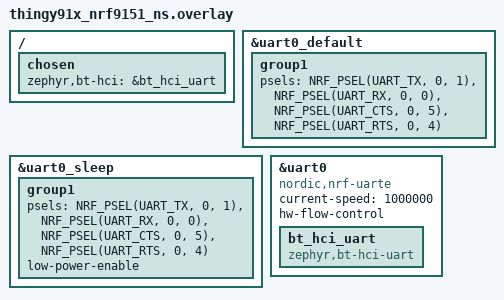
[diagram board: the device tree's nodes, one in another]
/*
 * Copyright (c) 2025 Golioth, Inc.
 *
 * SPDX-License-Identifier: Apache-2.0
 */

/ {
	chosen {
		zephyr,bt-hci = &bt_hci_uart;
		/delete-property/ zephyr,console;
		/delete-property/ zephyr,shell-uart;
		/delete-property/ zephyr,uart-mcumgr;
	};
};

&uart0_default {
	group1 {
		psels = <NRF_PSEL(UART_TX, 0, 1)>,
			<NRF_PSEL(UART_RX, 0, 0)>,
			<NRF_PSEL(UART_CTS, 0, 5)>,
			<NRF_PSEL(UART_RTS, 0, 4)>;
	};
};

&uart0_sleep {
	group1 {
		psels = <NRF_PSEL(UART_TX, 0, 1)>,
			<NRF_PSEL(UART_RX, 0, 0)>,
			<NRF_PSEL(UART_CTS, 0, 5)>,
			<NRF_PSEL(UART_RTS, 0, 4)>;
		low-power-enable;
	};
};

&uart0 {
	compatible = "nordic,nrf-uarte";
	status = "okay";
	current-speed = <1000000>;
	hw-flow-control;

	bt_hci_uart: bt_hci_uart {
		compatible = "zephyr,bt-hci-uart";
		status = "okay";
	};
};
